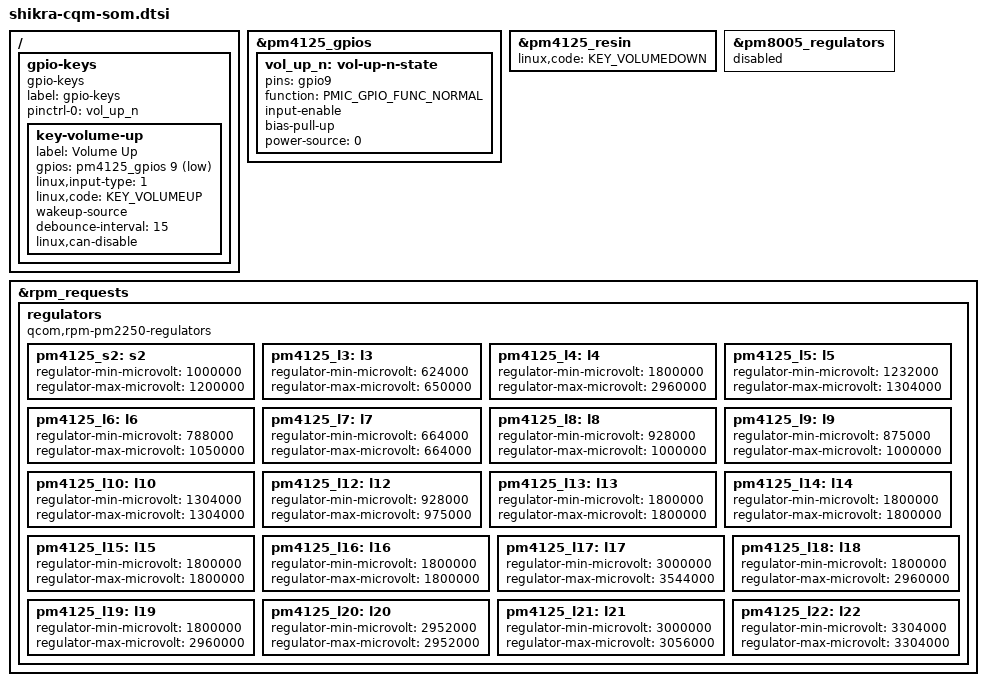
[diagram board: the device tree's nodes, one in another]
// SPDX-License-Identifier: BSD-3-Clause
/*
 * Copyright (c) Qualcomm Technologies, Inc. and/or its subsidiaries.
 */

#include <dt-bindings/gpio/gpio.h>
#include <dt-bindings/pinctrl/qcom,pmic-gpio.h>

#include "shikra.dtsi"
#include "pm4125.dtsi"
#include "pm8005.dtsi"

/ {
	gpio-keys {
		compatible = "gpio-keys";
		label = "gpio-keys";
		pinctrl-0 = <&vol_up_n>;
		pinctrl-names = "default";

		key-volume-up {
			label = "Volume Up";
			gpios = <&pm4125_gpios 9 GPIO_ACTIVE_LOW>;
			linux,input-type = <1>;
			linux,code = <KEY_VOLUMEUP>;
			wakeup-source;
			debounce-interval = <15>;
			linux,can-disable;
		};
	};
};

&pm4125_gpios {
	vol_up_n: vol-up-n-state {
		pins = "gpio9";
		function = PMIC_GPIO_FUNC_NORMAL;
		input-enable;
		bias-pull-up;
		power-source = <0>;
	};
};

&pm4125_resin {
	linux,code = <KEY_VOLUMEDOWN>;

	status = "okay";
};

&pm8005_regulators {
	status = "disabled";
};

&rpm_requests {
	regulators {
		compatible = "qcom,rpm-pm2250-regulators";

		pm4125_s2: s2 {
			regulator-min-microvolt = <1000000>;
			regulator-max-microvolt = <1200000>;
		};

		pm4125_l3: l3 {
			regulator-min-microvolt = <624000>;
			regulator-max-microvolt = <650000>;
		};

		pm4125_l4: l4 {
			regulator-min-microvolt = <1800000>;
			regulator-max-microvolt = <2960000>;
		};

		pm4125_l5: l5 {
			regulator-min-microvolt = <1232000>;
			regulator-max-microvolt = <1304000>;
		};

		pm4125_l6: l6 {
			regulator-min-microvolt = <788000>;
			regulator-max-microvolt = <1050000>;
		};

		pm4125_l7: l7 {
			regulator-min-microvolt = <664000>;
			regulator-max-microvolt = <664000>;
		};

		pm4125_l8: l8 {
			regulator-min-microvolt = <928000>;
			regulator-max-microvolt = <1000000>;
		};

		pm4125_l9: l9 {
			regulator-min-microvolt = <875000>;
			regulator-max-microvolt = <1000000>;
		};

		pm4125_l10: l10 {
			regulator-min-microvolt = <1304000>;
			regulator-max-microvolt = <1304000>;
		};

		pm4125_l12: l12 {
			regulator-min-microvolt = <928000>;
			regulator-max-microvolt = <975000>;
		};

		pm4125_l13: l13 {
			regulator-min-microvolt = <1800000>;
			regulator-max-microvolt = <1800000>;
		};

		pm4125_l14: l14 {
			regulator-min-microvolt = <1800000>;
			regulator-max-microvolt = <1800000>;
		};

		pm4125_l15: l15 {
			regulator-min-microvolt = <1800000>;
			regulator-max-microvolt = <1800000>;
		};

		pm4125_l16: l16 {
			regulator-min-microvolt = <1800000>;
			regulator-max-microvolt = <1800000>;
		};

		pm4125_l17: l17 {
			regulator-min-microvolt = <3000000>;
			regulator-max-microvolt = <3544000>;
		};

		pm4125_l18: l18 {
			regulator-min-microvolt = <1800000>;
			regulator-max-microvolt = <2960000>;
		};

		pm4125_l19: l19 {
			regulator-min-microvolt = <1800000>;
			regulator-max-microvolt = <2960000>;
		};

		pm4125_l20: l20 {
			regulator-min-microvolt = <2952000>;
			regulator-max-microvolt = <2952000>;
		};

		pm4125_l21: l21 {
			regulator-min-microvolt = <3000000>;
			regulator-max-microvolt = <3056000>;
		};

		pm4125_l22: l22 {
			regulator-min-microvolt = <3304000>;
			regulator-max-microvolt = <3304000>;
		};
	};
};
